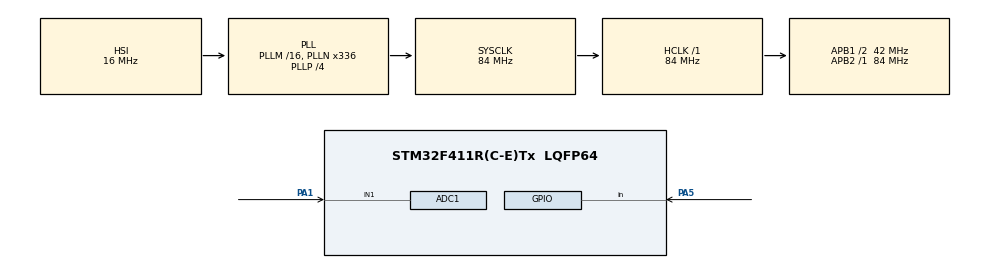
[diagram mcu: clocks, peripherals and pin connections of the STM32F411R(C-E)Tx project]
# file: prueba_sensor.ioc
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ADC1.Channel-0\#ChannelRegularConversion=ADC_CHANNEL_1
ADC1.NbrOfConversionFlag=1
ADC1.Rank-0\#ChannelRegularConversion=1
ADC1.SamplingTime-0\#ChannelRegularConversion=ADC_SAMPLETIME_3CYCLES
ADC1.master=1
Mcu.Family=STM32F4
Mcu.Name=STM32F411R(C-E)Tx
Mcu.Package=LQFP64
NVIC.PriorityGroup=NVIC_PRIORITYGROUP_0
PA1.Signal=ADCx_IN1
PA5.Signal=GPIO_Input
ProjectManager.HeapSize=0x200
ProjectManager.StackSize=0x400
ProjectManager.TargetToolchain=CMake
RCC.48MHZClocksFreq_Value=84000000
RCC.AHBFreq_Value=84000000
RCC.APB1CLKDivider=RCC_HCLK_DIV2
RCC.APB1Freq_Value=42000000
RCC.APB1TimFreq_Value=84000000
RCC.APB2Freq_Value=84000000
RCC.APB2TimFreq_Value=84000000
RCC.CortexFreq_Value=84000000
RCC.FLatency-AdvancedSettings=FLASH_LATENCY_2
RCC.HCLKFreq_Value=84000000
RCC.HSE_VALUE=8000000
RCC.HSI_VALUE=16000000
RCC.LSE_VALUE=32768
RCC.PLLN=336
RCC.PLLP=RCC_PLLP_DIV4
RCC.SYSCLKFreq_VALUE=84000000
RCC.SYSCLKSource=RCC_SYSCLKSOURCE_PLLCLK
RCC.VCOOutputFreq_Value=336000000
SH.ADCx_IN1.0=ADC1_IN1,IN1
board=NUCLEO-F411RE

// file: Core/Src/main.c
/* USER CODE BEGIN Header */
/**
  ******************************************************************************
  * @file           : main.c
  * @brief          : Main program body
  ******************************************************************************
  * @attention
  *
  * Copyright (c) 2026 STMicroelectronics.
  * All rights reserved.
  *
  * This software is licensed under terms that can be found in the LICENSE file
  * in the root directory of this software component.
  * If no LICENSE file comes with this software, it is provided AS-IS.
  *
  ******************************************************************************
  */
/* USER CODE END Header */
#include "main.h"
#include "adc.h"
#include "gpio.h"
#include "stm32f4xx_hal_adc.h"
#include "math.h"

/* USER CODE BEGIN PV */
float  convertAnalogToTemperature(float analogReadValue);
/* USER CODE END PV */

void SystemClock_Config(void);

/* USER CODE BEGIN 0 */
float adc = 0;
float temp = 0;
/* USER CODE END 0 */

int main(void)
{

  /* MCU Configuration--------------------------------------------------------*/

  /* Reset of all peripherals, Initializes the Flash interface and the Systick. */
  HAL_Init();

  /* Configure the system clock */
  SystemClock_Config();

  /* Initialize all configured peripherals */
  MX_GPIO_Init();
  MX_ADC1_Init();

  /* Infinite loop */
  while (1)
  {

    /* USER CODE BEGIN 3 */

    HAL_ADC_Start(&hadc1);
    HAL_ADC_PollForConversion(&hadc1, 100);
    adc = HAL_ADC_GetValue(&hadc1) / 6.6;
    HAL_ADC_Stop(&hadc1);

    temp = convertAnalogToTemperature(adc);

    HAL_Delay(500);

  }
  /* USER CODE END 3 */
}

void SystemClock_Config(void)
{
  RCC_OscInitTypeDef RCC_OscInitStruct = {0};
  RCC_ClkInitTypeDef RCC_ClkInitStruct = {0};

  /** Configure the main internal regulator output voltage
  */
  __HAL_RCC_PWR_CLK_ENABLE();
  __HAL_PWR_VOLTAGESCALING_CONFIG(PWR_REGULATOR_VOLTAGE_SCALE1);

  /** Initializes the RCC Oscillators according to the specified parameters
  * in the RCC_OscInitTypeDef structure.
  */
  RCC_OscInitStruct.OscillatorType = RCC_OSCILLATORTYPE_HSI;
  RCC_OscInitStruct.HSIState = RCC_HSI_ON;
  RCC_OscInitStruct.HSICalibrationValue = RCC_HSICALIBRATION_DEFAULT;
  RCC_OscInitStruct.PLL.PLLState = RCC_PLL_ON;
  RCC_OscInitStruct.PLL.PLLSource = RCC_PLLSOURCE_HSI;
  RCC_OscInitStruct.PLL.PLLM = 16;
  RCC_OscInitStruct.PLL.PLLN = 336;
  RCC_OscInitStruct.PLL.PLLP = RCC_PLLP_DIV4;
  RCC_OscInitStruct.PLL.PLLQ = 4;
  if (HAL_RCC_OscConfig(&RCC_OscInitStruct) != HAL_OK)
  {
    Error_Handler();
  }

  /** Initializes the CPU, AHB and APB buses clocks
  */
  RCC_ClkInitStruct.ClockType = RCC_CLOCKTYPE_HCLK|RCC_CLOCKTYPE_SYSCLK
                              |RCC_CLOCKTYPE_PCLK1|RCC_CLOCKTYPE_PCLK2;
  RCC_ClkInitStruct.SYSCLKSource = RCC_SYSCLKSOURCE_PLLCLK;
  RCC_ClkInitStruct.AHBCLKDivider = RCC_SYSCLK_DIV1;
  RCC_ClkInitStruct.APB1CLKDivider = RCC_HCLK_DIV2;
  RCC_ClkInitStruct.APB2CLKDivider = RCC_HCLK_DIV1;

  if (HAL_RCC_ClockConfig(&RCC_ClkInitStruct, FLASH_LATENCY_2) != HAL_OK)
  {
    Error_Handler();
  }
}

/* USER CODE BEGIN 4 */
float  convertAnalogToTemperature(float analogReadValue)
{
  // If analogReadValue is 0, we would otherwise cause a Divide-By-Zero,
  // Treat as crazy out-of-range temperature.
  if(analogReadValue == 0) return -1000.0;
  return (1/((log(((10000.0 * (1023.0 - analogReadValue)) / analogReadValue)/10000.0)/3435.0) + (1 / (273.15 + 25.000))) - 273.15);
}
/* USER CODE END 4 */

void Error_Handler(void)
{
  __disable_irq();
  while (1)
  {
  }
}
